AUTOSAR XML (schema 4-2-2)
package /IoHwAb_DIO
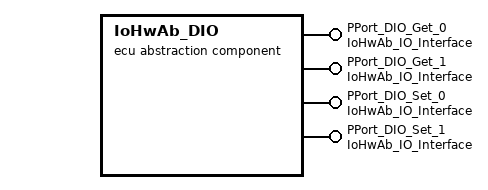
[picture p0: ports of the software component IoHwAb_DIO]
  ecu abstraction sw component type IoHwAb_DIO
    4 x provide port, all with provided-interface=IoHwAb_IO_Interface:
      PPort_DIO_Get_0
      PPort_DIO_Get_1
      PPort_DIO_Set_0
      PPort_DIO_Set_1
    behavior IB_IoHwAb_DIO
      4 x operation invoked event:
        OperationInvokedEvent_0: start-on-event=IoHwAb_DIO_Get_0, operation=PPort_DIO_Get_0.IoHwAb_IO_Get
        OperationInvokedEvent_1: start-on-event=IoHwAb_DIO_Set_1, operation=PPort_DIO_Set_1.IoHwAb_IO_Set
        OperationInvokedEvent_3: start-on-event=IoHwAb_DIO_Get_1, operation=PPort_DIO_Get_1.IoHwAb_IO_Get
        OperationInvokedEvent_4: start-on-event=IoHwAb_DIO_Set_0, operation=PPort_DIO_Set_0.IoHwAb_IO_Set
      4 x runnable:
        IoHwAb_DIO_Get_0: symbol=IoHwAb_DIO_Get_0_func
        IoHwAb_DIO_Get_1: symbol=IoHwAb_DIO_Get_1_func
        IoHwAb_DIO_Set_0: symbol=IoHwAb_DIO_Set_0_func
        IoHwAb_DIO_Set_1: symbol=IoHwAb_DIO_Set_1_func
